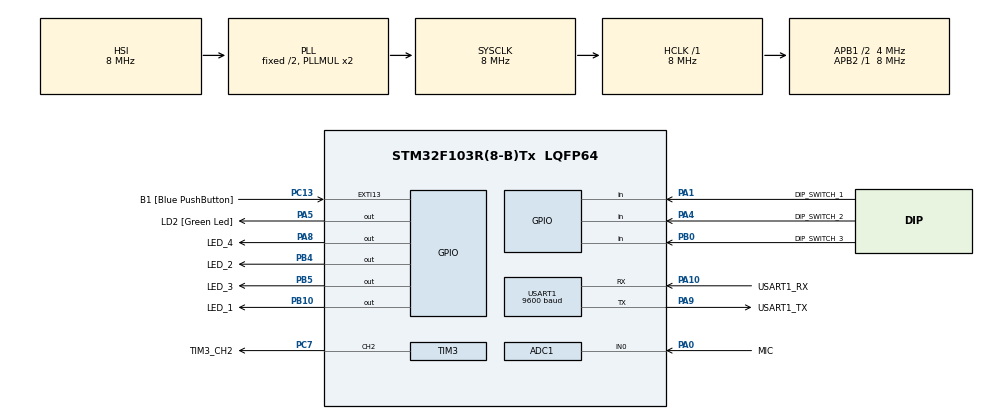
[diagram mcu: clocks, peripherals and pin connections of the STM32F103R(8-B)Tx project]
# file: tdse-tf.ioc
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ADC1.Channel-1\#ChannelRegularConversion=ADC_CHANNEL_0
ADC1.NbrOfConversionFlag=1
ADC1.Rank-1\#ChannelRegularConversion=1
ADC1.SamplingTime-1\#ChannelRegularConversion=ADC_SAMPLETIME_1CYCLE_5
ADC1.master=1
Mcu.Family=STM32F1
Mcu.Name=STM32F103R(8-B)Tx
Mcu.Package=LQFP64
NVIC.EXTI15_10_IRQn=true\:0\:0\:false\:false\:true\:true\:true\:true
NVIC.PriorityGroup=NVIC_PRIORITYGROUP_4
NVIC.TIM2_IRQn=true\:0\:0\:false\:false\:true\:true\:true\:true
NVIC.USART1_IRQn=true\:0\:0\:false\:false\:true\:true\:true\:true
PA0-WKUP.GPIO_Label=MIC
PA0-WKUP.Signal=ADCx_IN0
PA1.GPIO_Label=DIP_SWITCH_1
PA1.GPIO_PuPd=GPIO_PULLUP
PA1.Signal=GPIO_Input
PA10.GPIO_Label=USART1_RX
PA10.GPIO_PuPd=GPIO_PULLUP
PA10.Mode=Asynchronous
PA10.Signal=USART1_RX
PA13.GPIO_Label=TMS
PA13.Mode=Serial_Wire
PA13.Signal=SYS_JTMS-SWDIO
PA14.GPIO_Label=TCK
PA14.Mode=Serial_Wire
PA14.Signal=SYS_JTCK-SWCLK
PA3.GPIO_Label=USART_RX
PA3.GPIO_Mode=GPIO_MODE_INPUT
PA3.GPIO_PuPd=GPIO_PULLUP
PA3.GPIO_Speed=GPIO_SPEED_FREQ_LOW
PA3.Signal=USART2_RX
PA4.GPIO_Label=DIP_SWITCH_2
PA4.GPIO_PuPd=GPIO_PULLUP
PA4.Signal=GPIO_Input
PA5.GPIO_Label=LD2 [Green Led]
PA5.GPIO_ModeDefaultOutputPP=GPIO_MODE_OUTPUT_PP
PA5.GPIO_PuPd=GPIO_NOPULL
PA5.GPIO_Speed=GPIO_SPEED_FREQ_LOW
PA5.Signal=GPIO_Output
PA8.GPIO_Label=LED_4
PA8.GPIO_PuPd=GPIO_NOPULL
PA8.Signal=GPIO_Output
PA9.GPIO_Label=USART1_TX
PA9.Mode=Asynchronous
PA9.Signal=USART1_TX
PB0.GPIO_Label=DIP_SWITCH_3
PB0.GPIO_PuPd=GPIO_PULLUP
PB0.Signal=GPIO_Input
PB10.GPIO_Label=LED_1
PB10.Signal=GPIO_Output
PB3.GPIO_Label=SWO
PB3.Signal=SYS_JTDO-TRACESWO
PB4.GPIO_Label=LED_2
PB4.Signal=GPIO_Output
PB5.GPIO_Label=LED_3
PB5.Signal=GPIO_Output
PC13-TAMPER-RTC.GPIO_Label=B1 [Blue PushButton]
PC13-TAMPER-RTC.GPIO_PuPd=GPIO_NOPULL
PC13-TAMPER-RTC.Signal=GPXTI13
PC14-OSC32_IN.Mode=LSE-External-Oscillator
PC14-OSC32_IN.Signal=RCC_OSC32_IN
PC15-OSC32_OUT.Mode=LSE-External-Oscillator
PC15-OSC32_OUT.Signal=RCC_OSC32_OUT
PC7.GPIO_Label=TIM3_CH2
PC7.Signal=S_TIM3_CH2
PD0-OSC_IN.Mode=HSE-External-Clock-Source
PD0-OSC_IN.Signal=RCC_OSC_IN
PD1-OSC_OUT.Mode=HSE-External-Clock-Source
PD1-OSC_OUT.Signal=RCC_OSC_OUT
ProjectManager.HeapSize=0x200
ProjectManager.StackSize=0x400
ProjectManager.TargetToolchain=STM32CubeIDE
RCC.AHBFreq_Value=8000000
RCC.APB1CLKDivider=RCC_HCLK_DIV2
RCC.APB1Freq_Value=4000000
RCC.APB1TimFreq_Value=8000000
RCC.APB2Freq_Value=8000000
RCC.APB2TimFreq_Value=8000000
RCC.HCLKFreq_Value=8000000
RCC.RTCClockSelection=RCC_RTCCLKSOURCE_LSE
RCC.SYSCLKFreq_VALUE=8000000
RCC.SYSCLKSource=RCC_SYSCLKSOURCE_PLLCLK
RCC.USBFreq_Value=8000000
SH.ADCx_IN0.0=ADC1_IN0,IN0
SH.S_TIM3_CH2.0=TIM3_CH2,PWM Generation2 CH2
TIM2.Period=124
TIM2.Prescaler=71
TIM3.Channel-PWM\ Generation2\ CH2=TIM_CHANNEL_2
TIM3.Period=499
TIM3.Prescaler=7
TIM3.Pulse-PWM\ Generation2\ CH2=250
USART1.BaudRate=9600
USART1.VirtualMode=VM_ASYNC
VP_TIM2_VS_ClockSourceINT.Mode=Internal
VP_TIM3_VS_ClockSourceINT.Mode=Internal
board=NUCLEO-F103RB

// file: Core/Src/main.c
/* USER CODE BEGIN Header */
/**
  ******************************************************************************
  * @file           : main.c
  * @brief          : Main program body
  ******************************************************************************
  * @attention
  *
  * Copyright (c) 2026 STMicroelectronics.
  * All rights reserved.
  *
  * This software is licensed under terms that can be found in the LICENSE file
  * in the root directory of this software component.
  * If no LICENSE file comes with this software, it is provided AS-IS.
  *
  ******************************************************************************
  */
/* USER CODE END Header */
#include "main.h"

/* USER CODE BEGIN Includes */
#include <stdio.h>
#include <string.h>

/* Application includes */
#include "config.h"
#include "app_main.h"
#include "logger.h"
#include "bluetooth.h"
#include "mic.h"
#include "dwt.h"
#include "sound_detector.h"
#include "board.h"
/* USER CODE END Includes */

ADC_HandleTypeDef hadc1;

TIM_HandleTypeDef htim2;
TIM_HandleTypeDef htim3;

UART_HandleTypeDef huart1;

void SystemClock_Config(void);
static void MX_GPIO_Init(void);
static void MX_ADC1_Init(void);
static void MX_TIM2_Init(void);
static void MX_USART1_UART_Init(void);
static void MX_TIM3_Init(void);

/* USER CODE BEGIN 0 */
#if (1 == LOGGER_CONFIG_USE_SEMIHOSTING)
extern void initialise_monitor_handles(void);
#endif

static uint8_t rx_byte;
/* USER CODE END 0 */

int main(void)
{

  /* USER CODE BEGIN 1 */
	#if (1 == LOGGER_CONFIG_USE_SEMIHOSTING)
	initialise_monitor_handles();
	#endif
  /* USER CODE END 1 */

  /* MCU Configuration--------------------------------------------------------*/

  /* Reset of all peripherals, Initializes the Flash interface and the Systick. */
  HAL_Init();

  /* Configure the system clock */
  SystemClock_Config();
  cycle_counter_init();

  /* Initialize all configured peripherals */
  MX_GPIO_Init();
  MX_ADC1_Init();
  MX_TIM2_Init();
  MX_USART1_UART_Init();
  MX_TIM3_Init();
  /* USER CODE BEGIN 2 */
  Config_Init();
  App_Init();
  HAL_UART_Receive_IT(&huart1, &rx_byte, 1);
  HAL_TIM_Base_Start_IT(&htim2);
  // PRUEBA
  /* USER CODE END 2 */

  /* Infinite loop */
  /* USER CODE BEGIN WHILE */

  //uint32_t start_time = HAL_GetTick();

  //while ((HAL_GetTick() - start_time) < 60000) 	//60 segundos para testear todas las acciones y medir los wcet
  while(1)
  {
    /* USER CODE END WHILE */

    /* USER CODE BEGIN 3 */
	App_Loop();

  }

/*
  LOGGER_INFO("----- WCET RESULTS -----");
  LOGGER_INFO("Mode update: %lu us", wcet_mode_update);
  LOGGER_INFO("Send status update: %lu us", wcet_send_status);
  LOGGER_INFO("Receive status update: %lu us", wcet_receive_status);
  LOGGER_INFO("Send alert: %lu us", wcet_send_alert);
  LOGGER_INFO("leds update: %lu us", wcet_leds_update);

  while(1);
*/
  /* USER CODE END 3 */
}

void SystemClock_Config(void)
{
  RCC_OscInitTypeDef RCC_OscInitStruct = {0};
  RCC_ClkInitTypeDef RCC_ClkInitStruct = {0};
  RCC_PeriphCLKInitTypeDef PeriphClkInit = {0};

  /** Initializes the RCC Oscillators according to the specified parameters
  * in the RCC_OscInitTypeDef structure.
  */
  RCC_OscInitStruct.OscillatorType = RCC_OSCILLATORTYPE_HSI;
  RCC_OscInitStruct.HSIState = RCC_HSI_ON;
  RCC_OscInitStruct.HSICalibrationValue = RCC_HSICALIBRATION_DEFAULT;
  RCC_OscInitStruct.PLL.PLLState = RCC_PLL_ON;
  RCC_OscInitStruct.PLL.PLLSource = RCC_PLLSOURCE_HSI_DIV2;
  RCC_OscInitStruct.PLL.PLLMUL = RCC_PLL_MUL2;
  if (HAL_RCC_OscConfig(&RCC_OscInitStruct) != HAL_OK)
  {
    Error_Handler();
  }

  /** Initializes the CPU, AHB and APB buses clocks
  */
  RCC_ClkInitStruct.ClockType = RCC_CLOCKTYPE_HCLK|RCC_CLOCKTYPE_SYSCLK
                              |RCC_CLOCKTYPE_PCLK1|RCC_CLOCKTYPE_PCLK2;
  RCC_ClkInitStruct.SYSCLKSource = RCC_SYSCLKSOURCE_PLLCLK;
  RCC_ClkInitStruct.AHBCLKDivider = RCC_SYSCLK_DIV1;
  RCC_ClkInitStruct.APB1CLKDivider = RCC_HCLK_DIV2;
  RCC_ClkInitStruct.APB2CLKDivider = RCC_HCLK_DIV1;

  if (HAL_RCC_ClockConfig(&RCC_ClkInitStruct, FLASH_LATENCY_0) != HAL_OK)
  {
    Error_Handler();
  }
  PeriphClkInit.PeriphClockSelection = RCC_PERIPHCLK_ADC;
  PeriphClkInit.AdcClockSelection = RCC_ADCPCLK2_DIV2;
  if (HAL_RCCEx_PeriphCLKConfig(&PeriphClkInit) != HAL_OK)
  {
    Error_Handler();
  }
}

static void MX_ADC1_Init(void)
{

  ADC_ChannelConfTypeDef sConfig = {0};

  /** Common config
  */
  hadc1.Instance = ADC1;
  hadc1.Init.ScanConvMode = ADC_SCAN_DISABLE;
  hadc1.Init.ContinuousConvMode = DISABLE;
  hadc1.Init.DiscontinuousConvMode = DISABLE;
  hadc1.Init.ExternalTrigConv = ADC_SOFTWARE_START;
  hadc1.Init.DataAlign = ADC_DATAALIGN_RIGHT;
  hadc1.Init.NbrOfConversion = 1;
  if (HAL_ADC_Init(&hadc1) != HAL_OK)
  {
    Error_Handler();
  }

  /** Configure Regular Channel
  */
  sConfig.Channel = ADC_CHANNEL_0;
  sConfig.Rank = ADC_REGULAR_RANK_1;
  sConfig.SamplingTime = ADC_SAMPLETIME_1CYCLE_5;
  if (HAL_ADC_ConfigChannel(&hadc1, &sConfig) != HAL_OK)
  {
    Error_Handler();
  }

}

static void MX_TIM2_Init(void)
{

  TIM_ClockConfigTypeDef sClockSourceConfig = {0};
  TIM_MasterConfigTypeDef sMasterConfig = {0};

  htim2.Instance = TIM2;
  htim2.Init.Prescaler = 71;
  htim2.Init.CounterMode = TIM_COUNTERMODE_UP;
  htim2.Init.Period = 124;
  htim2.Init.ClockDivision = TIM_CLOCKDIVISION_DIV1;
  htim2.Init.AutoReloadPreload = TIM_AUTORELOAD_PRELOAD_DISABLE;
  if (HAL_TIM_Base_Init(&htim2) != HAL_OK)
  {
    Error_Handler();
  }
  sClockSourceConfig.ClockSource = TIM_CLOCKSOURCE_INTERNAL;
  if (HAL_TIM_ConfigClockSource(&htim2, &sClockSourceConfig) != HAL_OK)
  {
    Error_Handler();
  }
  sMasterConfig.MasterOutputTrigger = TIM_TRGO_RESET;
  sMasterConfig.MasterSlaveMode = TIM_MASTERSLAVEMODE_DISABLE;
  if (HAL_TIMEx_MasterConfigSynchronization(&htim2, &sMasterConfig) != HAL_OK)
  {
    Error_Handler();
  }

}

static void MX_TIM3_Init(void)
{

  TIM_ClockConfigTypeDef sClockSourceConfig = {0};
  TIM_MasterConfigTypeDef sMasterConfig = {0};
  TIM_OC_InitTypeDef sConfigOC = {0};

  htim3.Instance = TIM3;
  htim3.Init.Prescaler = 7;
  htim3.Init.CounterMode = TIM_COUNTERMODE_UP;
  htim3.Init.Period = 499;
  htim3.Init.ClockDivision = TIM_CLOCKDIVISION_DIV1;
  htim3.Init.AutoReloadPreload = TIM_AUTORELOAD_PRELOAD_DISABLE;
  if (HAL_TIM_Base_Init(&htim3) != HAL_OK)
  {
    Error_Handler();
  }
  sClockSourceConfig.ClockSource = TIM_CLOCKSOURCE_INTERNAL;
  if (HAL_TIM_ConfigClockSource(&htim3, &sClockSourceConfig) != HAL_OK)
  {
    Error_Handler();
  }
  if (HAL_TIM_PWM_Init(&htim3) != HAL_OK)
  {
    Error_Handler();
  }
  sMasterConfig.MasterOutputTrigger = TIM_TRGO_RESET;
  sMasterConfig.MasterSlaveMode = TIM_MASTERSLAVEMODE_DISABLE;
  if (HAL_TIMEx_MasterConfigSynchronization(&htim3, &sMasterConfig) != HAL_OK)
  {
    Error_Handler();
  }
  sConfigOC.OCMode = TIM_OCMODE_PWM1;
  sConfigOC.Pulse = 250;
  sConfigOC.OCPolarity = TIM_OCPOLARITY_HIGH;
  sConfigOC.OCFastMode = TIM_OCFAST_DISABLE;
  if (HAL_TIM_PWM_ConfigChannel(&htim3, &sConfigOC, TIM_CHANNEL_2) != HAL_OK)
  {
    Error_Handler();
  }
  HAL_TIM_MspPostInit(&htim3);

}

static void MX_USART1_UART_Init(void)
{

  huart1.Instance = USART1;
  huart1.Init.BaudRate = 9600;
  huart1.Init.WordLength = UART_WORDLENGTH_8B;
  huart1.Init.StopBits = UART_STOPBITS_1;
  huart1.Init.Parity = UART_PARITY_NONE;
  huart1.Init.Mode = UART_MODE_TX_RX;
  huart1.Init.HwFlowCtl = UART_HWCONTROL_NONE;
  huart1.Init.OverSampling = UART_OVERSAMPLING_16;
  if (HAL_UART_Init(&huart1) != HAL_OK)
  {
    Error_Handler();
  }

}

static void MX_GPIO_Init(void)
{
  GPIO_InitTypeDef GPIO_InitStruct = {0};

  /* GPIO Ports Clock Enable */
  __HAL_RCC_GPIOC_CLK_ENABLE();
  __HAL_RCC_GPIOD_CLK_ENABLE();
  __HAL_RCC_GPIOA_CLK_ENABLE();
  __HAL_RCC_GPIOB_CLK_ENABLE();

  /*Configure GPIO pin Output Level */
  HAL_GPIO_WritePin(GPIOA, LD2_Pin|LED_4_Pin, GPIO_PIN_RESET);

  /*Configure GPIO pin Output Level */
  HAL_GPIO_WritePin(GPIOB, LED_1_Pin|LED_2_Pin|LED_3_Pin, GPIO_PIN_RESET);

  /*Configure GPIO pin : B1_Pin */
  GPIO_InitStruct.Pin = B1_Pin;
  GPIO_InitStruct.Mode = GPIO_MODE_IT_RISING;
  GPIO_InitStruct.Pull = GPIO_NOPULL;
  HAL_GPIO_Init(B1_GPIO_Port, &GPIO_InitStruct);

  /*Configure GPIO pins : DIP_SWITCH_1_Pin USART_RX_Pin DIP_SWITCH_2_Pin */
  GPIO_InitStruct.Pin = DIP_SWITCH_1_Pin|USART_RX_Pin|DIP_SWITCH_2_Pin;
  GPIO_InitStruct.Mode = GPIO_MODE_INPUT;
  GPIO_InitStruct.Pull = GPIO_PULLUP;
  HAL_GPIO_Init(GPIOA, &GPIO_InitStruct);

  /*Configure GPIO pins : LD2_Pin LED_4_Pin */
  GPIO_InitStruct.Pin = LD2_Pin|LED_4_Pin;
  GPIO_InitStruct.Mode = GPIO_MODE_OUTPUT_PP;
  GPIO_InitStruct.Pull = GPIO_NOPULL;
  GPIO_InitStruct.Speed = GPIO_SPEED_FREQ_LOW;
  HAL_GPIO_Init(GPIOA, &GPIO_InitStruct);

  /*Configure GPIO pin : DIP_SWITCH_3_Pin */
  GPIO_InitStruct.Pin = DIP_SWITCH_3_Pin;
  GPIO_InitStruct.Mode = GPIO_MODE_INPUT;
  GPIO_InitStruct.Pull = GPIO_PULLUP;
  HAL_GPIO_Init(DIP_SWITCH_3_GPIO_Port, &GPIO_InitStruct);

  /*Configure GPIO pins : LED_1_Pin LED_2_Pin LED_3_Pin */
  GPIO_InitStruct.Pin = LED_1_Pin|LED_2_Pin|LED_3_Pin;
  GPIO_InitStruct.Mode = GPIO_MODE_OUTPUT_PP;
  GPIO_InitStruct.Pull = GPIO_NOPULL;
  GPIO_InitStruct.Speed = GPIO_SPEED_FREQ_LOW;
  HAL_GPIO_Init(GPIOB, &GPIO_InitStruct);

  /*Configure GPIO pin : BLE_STATE_Pin */
  GPIO_InitStruct.Pin = BLE_STATE_Pin;
  GPIO_InitStruct.Mode = GPIO_MODE_IT_RISING_FALLING;
  GPIO_InitStruct.Pull = GPIO_PULLDOWN;
  HAL_GPIO_Init(BLE_STATE_GPIO_Port, &GPIO_InitStruct);

  /* EXTI interrupt init*/
  HAL_NVIC_SetPriority(EXTI9_5_IRQn, 0, 0);
  HAL_NVIC_EnableIRQ(EXTI9_5_IRQn);

  HAL_NVIC_SetPriority(EXTI15_10_IRQn, 0, 0);
  HAL_NVIC_EnableIRQ(EXTI15_10_IRQn);

}

/* USER CODE BEGIN 4 */
void HAL_UART_RxCpltCallback(UART_HandleTypeDef *huart)
{
    if (huart->Instance == USART1)
    {
        Bluetooth_OnRxByte(rx_byte);
        HAL_UART_Receive_IT(&huart1, &rx_byte, 1);
    }
}

void HAL_TIM_PeriodElapsedCallback(TIM_HandleTypeDef *htim)
{
    if (htim->Instance != TIM2)
        return;

    uint16_t sample = Mic_ReadRaw();

    if (Sound_IsDetected(sample, mic_offset))
	{
		sound_alert_flag = 1;
	}

}

void HAL_GPIO_EXTI_Callback(uint16_t GPIO_Pin)
{
    if (GPIO_Pin == BLE_STATE_Pin)
    {
    	ble_connected = Bluetooth_IsConnected();
    }
}
/* USER CODE END 4 */

void Error_Handler(void)
{
  __disable_irq();
  while (1)
  {
  }
}
